# R7FA8D1BH register map
Vendor: Renesas; Series: RA8; File version: 1.2
CPU: CM85 r0p0, little endian, MPU, FPU, VTOR, 4 interrupt priority bits
Registers are 32-bit, read-write, reset 0x0 unless marked. A register's access mark holds for its fields unless they carry their own. Offsets are from the block's base; [hi:lo] are bit positions; {n}, {i} and the like mark numbered series; 'fields as' and 'values as' point back to an identical list.

## CANFD0 (part 2 of 2) — CANFD Module 0
Base 0x40380000
Same registers: CANFD1 0x40382000, CANFD0_NS 0x50380000, CANFD1_NS 0x50382000
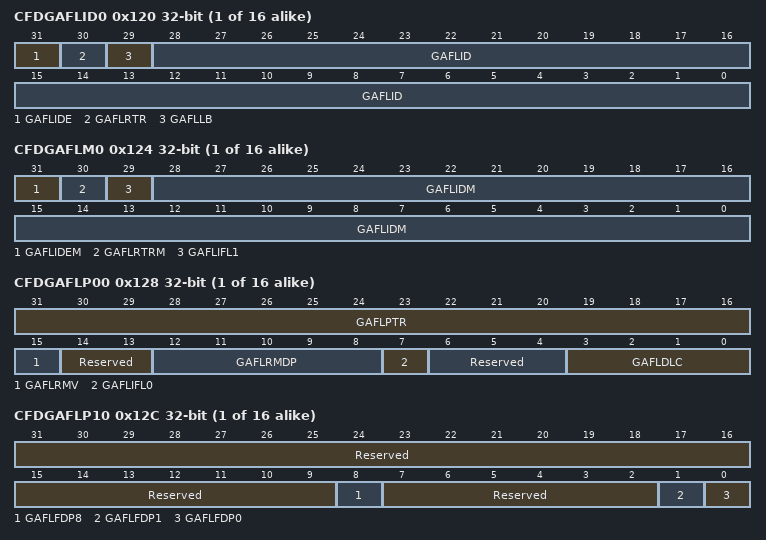
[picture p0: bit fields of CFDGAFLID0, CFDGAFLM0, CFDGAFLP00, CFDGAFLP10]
{0x120+0x10*i} CFDGAFLID{i} (i=0..15) — Global Acceptance Filter List ID Registers r = [1...10]h
  [31] GAFLIDE — Global Acceptance Filter List Entry IDE Field
    0=Standard Identifier of Rule entry ID is valid for acceptance filtering; 1=Extended Identifier of Rule entry ID is valid for acceptance filtering
  [30] GAFLRTR — Global Acceptance Filter List Entry RTR Field
    0=Data Frame; 1=Remote Frame
  [29] GAFLLB — Global Acceptance Filter List Entry Loopback Configuration
    0=Global Acceptance Filter List entry ID for acceptance filtering has attribute ‘RX’; 1=Global Acceptance Filter List entry ID for acceptance filtering has attribute ‘TX’
  [28:0] GAFLID — Global Acceptance Filter List Entry ID Field
{0x124+0x10*i} CFDGAFLM{i} (i=0..15) — Global Acceptance Filter List Mask Registers r = [1...10]h
  [31] GAFLIDEM — Global Acceptance Filter List IDE Mask
    0=IDE bit is not considered for ID matching; 1=IDE bit is considered for ID matching
  [30] GAFLRTRM — Global Acceptance Filter List Entry RTR Mask
    0=RTR bit is not considered for ID matching; 1=RTR bit is considered for ID matching
  [29] GAFLIFL1 — Global Acceptance Filter List Information Label 1
  [28:0] GAFLIDM — Global Acceptance Filter List ID Mask Field
{0x128+0x10*i} CFDGAFLP0{i} (i=0..15) — Global Acceptance Filter List Pointer 0 Registers r = [1...10]h
  [31:16] GAFLPTR — Global Acceptance Filter List Pointer Field
    values as CFDGAFLM0.GAFLRTRM
  [15] GAFLRMV — Global Acceptance Filter List RX Message Buffer Valid
    0=Global Acceptance Filter List Single Message Buffer Direction Pointer is invalid; 1=Global Acceptance Filter List Single Message Buffer Direction Pointer is valid
  [14:13] Reserved — These bits are read as 00. The write value should be 00.
  [12:8] GAFLRMDP — Global Acceptance Filter List RX Message Buffer Direction Pointer
  [7] GAFLIFL0 — Global Acceptance Filter List Information Label 0
  [6:4] Reserved — These bits are read as 000. The write value should be 000.
  [3:0] GAFLDLC — Global Acceptance Filter List DLC Field
{0x12C+0x10*i} CFDGAFLP1{i} (i=0..15) — Global Acceptance Filter List Pointer 1 Registers r = [1...10]h
  [31:9] Reserved — These bits are read as 00000000000000000000000. The write value should be 00000000000000000000000.
  [8] GAFLFDP8 — Global Acceptance Filter List FIFO Direction Pointer (GAFLFDP[8])
  [7:2] Reserved — These bits are read as 000000. The write value should be 000000.
  [1] GAFLFDP1 — Global Acceptance Filter List FIFO Direction Pointer (GAFLFDP[1])
  [0] GAFLFDP0 — Global Acceptance Filter List FIFO Direction Pointer (GAFLFDP[0])
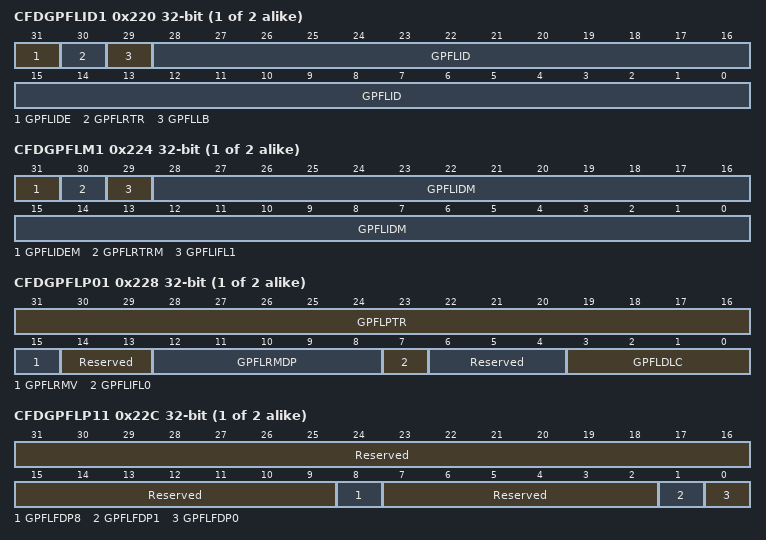
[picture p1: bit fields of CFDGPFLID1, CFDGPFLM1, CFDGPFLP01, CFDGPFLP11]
{0x1FC+0x24*i} CFDGPFLID{i} (i=1..2) — Global Pretended Network Filter List ID Registers s = [1…2]h
  [31] GPFLIDE — Global Pretended Network Filter List IDE Field
    values as CFDGAFLID0.GAFLIDE
  [30] GPFLRTR — Global Pretended Network Filter List Entry RTR Field
    0=Data Frame; 1=Remote Frame
  [29] GPFLLB — Global Pretended Network Filter List Entry Loopback Configuration
    0=Global Pretended Network Filter List entry ID for acceptance filtering has attribute ‘RX’; 1=Global Pretended Network Filter List entry ID for acceptance filtering has attribute ‘TX’
  [28:0] GPFLID — Global Pretended Network Filter List ID Field
{0x200+0x24*i} CFDGPFLM{i} (i=1..2) — Global Pretended Network Filter List MASK Registers s = [1…2]h
  [31] GPFLIDEM — Global Pretended Network Filter List IDE Mask
    values as CFDGAFLM0.GAFLIDEM
  [30] GPFLRTRM — Global Pretended Network Filter List Entry RTR Mask
    values as CFDGAFLM0.GAFLRTRM
  [29] GPFLIFL1 — Global Pretended Network Filter List Information Label 1
  [28:0] GPFLIDM — Global Pretended Network Filter List ID Mask Field
{0x204+0x24*i} CFDGPFLP0{i} (i=1..2) — Global Pretended Network Filter List Pointer 0 Registers s = [1…2]h
  [31:16] GPFLPTR — Global Pretended Network Filter List Pointer Field
  [15] GPFLRMV — Global Pretended Network Filter List RX Message Buffer Valid
    0=Global Pretended Network Filter List Single Message Buffer Direction Pointer is invalid; 1=Global Pretended Network Filter List Single Message Buffer Direction Pointer is valid
  [14:13] Reserved — These bits are read as 00. The write value should be 00.
  [12:8] GPFLRMDP — Global Pretended Network Filter List RX Message Buffer Direction Pointer
  [7] GPFLIFL0 — Global Pretended Network Filter List Information Label 0
  [6:4] Reserved — These bits are read as 000. The write value should be 000.
  [3:0] GPFLDLC — Global Pretended Network Filter List DLC Field
{0x208+0x24*i} CFDGPFLP1{i} (i=1..2) — Global Pretended Network Filter List Pointer 1 Registers s = [1…2]h
  [31:9] Reserved — These bits are read as 00000000000000000000000. The write value should be 00000000000000000000000.
  [8] GPFLFDP8 — Global Pretended Network Filter List FIFO Direction Pointer [8]
  [7:2] Reserved — These bits are read as 000000. The write value should be 000000.
  [1] GPFLFDP1 — Global Pretended Network Filter List FIFO Direction Pointer [1]
  [0] GPFLFDP0 — Global Pretended Network Filter List FIFO Direction Pointer [0]
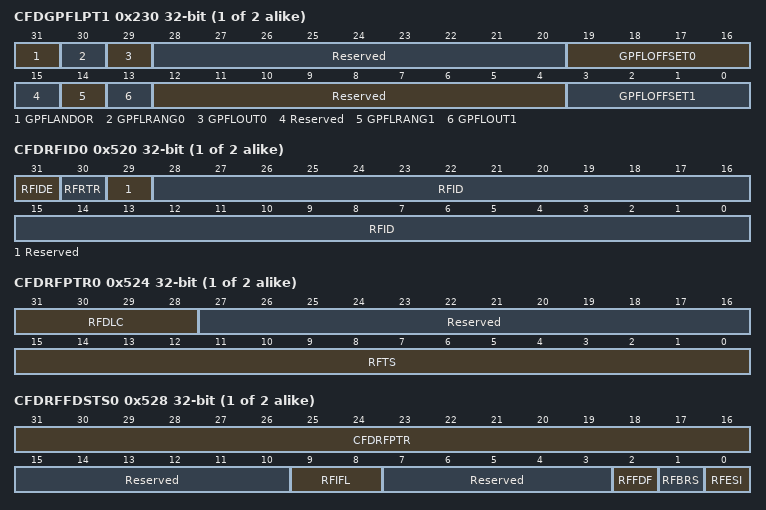
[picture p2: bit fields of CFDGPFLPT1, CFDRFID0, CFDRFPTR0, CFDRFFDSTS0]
{0x20C+0x24*i} CFDGPFLPT{i} (i=1..2) — Global Pretended Network Filter List Filter Type Registers s = [1…2]h
  [31] GPFLANDOR — Global Pretended Network filter conditions of the filters 0 and 1
    0=Both of filters 0 and 1 are successful; 1=One of the filter 0 or 1 is successful
  [30] GPFLRANG0 — Global Pretended Network filter comparison conditions of the filter0
    0=payload data match filter; 1=upper / lower filter
  [29] GPFLOUT0 — Global Pretended Network filter conditions of upper / lower filter of the filter0
    0=Within the range of upper limit and lower limit; 1=Outside of the range of upper limit and lower limit
  [28:20] Reserved — These bits are read as 000000000. The write value should be 000000000.
  [19:16] GPFLOFFSET0 — Global Pretended Network filter offset value of the filter0
  [15] Reserved — This bit is read as 0. The write value should be 0.
  [14] GPFLRANG1 — Global Pretended Network filter comparison conditions of the filter1
    0=payload data match filter; 1=upper / lower filter
  [13] GPFLOUT1 — Global Pretended Network filter conditions of upper / lower filter of the filter1
    values as GPFLOUT0
  [12:4] Reserved — These bits are read as 000000000. The write value should be 000000000.
  [3:0] GPFLOFFSET1 — Global Pretended Network filter offset value of the filter1
{0x210+0x24*i} CFDGPFLPD0{i} (i=1..2) — Global Pretended Network Filter List Payload Data 0 Registers s = [1…2]h
  [31:0] FDATA — Pretended Network Filter List Filter data
{0x214+0x24*i} CFDGPFLPM0{i} (i=1..2) — Global Pretended Network Filter List Payload Mask 0 Registers s = [1…2]h
  [31:0] FMASK — Pretended Network Filter List Filter data mask field
{0x218+0x24*i} CFDGPFLPD1{i} (i=1..2) — Global Pretended Network Filter List Payload Data 1 Registers s = [1…2]h
  [31:0] FDATA — Pretended Network Filter List Filter data
{0x21C+0x24*i} CFDGPFLPM1{i} (i=1..2) — Global Pretended Network Filter List Payload Mask 1 Registers s = [1…2]h
  [31:0] FMASK — Pretended Network Filter List Filter data mask field
{0x280+4i} CFDRPGACC{i} (i=0..63) — RAM Test Page Access Registers
  [31:0] RDTA — RAM Data Test Access
{0x520+0x4C*i} CFDRFID{i} (i=0..1) ro — RX FIFO Access ID Registers
  [31] RFIDE — RX FIFO Buffer IDE Bit
    0=STD-ID has been received; 1=EXT-ID has been received
  [30] RFRTR — RX FIFO Buffer RTR Bit
    0=Data Frame; 1=Remote Frame
  [29] Reserved — This bit is read as 0.
  [28:0] RFID — RX FIFO Buffer ID Field
{0x524+0x4C*i} CFDRFPTR{i} (i=0..1) ro — RX FIFO Access Pointer Register
  [31:28] RFDLC — RX FIFO Buffer DLC Field
    0=Data Frame; 1=Remote Frame
  [27:16] Reserved — These bits are read as 000000000000.
  [15:0] RFTS — RX FIFO Timestamp Value
{0x528+0x4C*i} CFDRFFDSTS{i} (i=0..1) ro — RX FIFO Access CAN-FD Status Register
  [31:16] CFDRFPTR — RX FIFO Buffer Pointer Field
  [15:10] Reserved — These bits are read as 000000.
  [9:8] RFIFL — RX FIFO Buffer Information label Field
  [7:3] Reserved — These bits are read as 00000.
  [2] RFFDF — CAN FD Format bit
    0=Non CAN-FD frame received; 1=CAN-FD frame received
  [1] RFBRS — Bit Rate Switch bit
    0=CAN-FD frame received with no bit rate switch; 1=CAN-FD frame received with bit rate switch
  [0] RFESI — Error State Indicator bit
    0=CAN-FD frame received from error active node; 1=CAN-FD frame received from error passive node
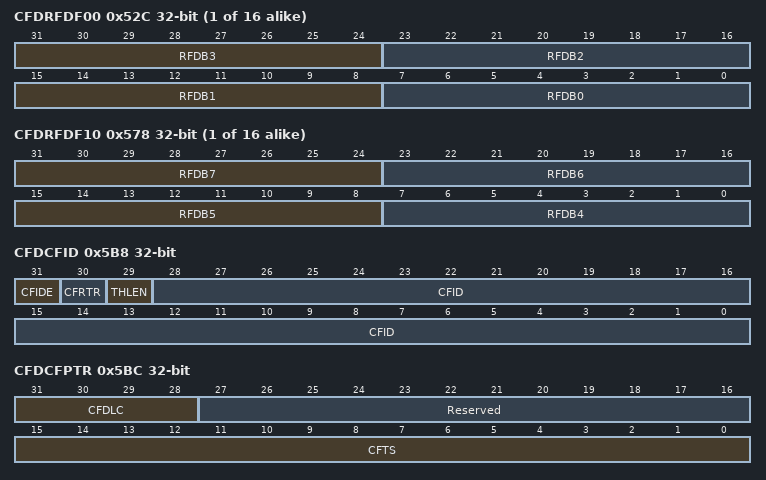
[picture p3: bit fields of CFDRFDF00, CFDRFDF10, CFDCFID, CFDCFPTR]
{0x52C+4i} CFDRFDF0{i} (i=0..15) ro — RX FIFO Access Data Field p Registers
  [31:24] RFDB3 — RX FIFO Buffer Data Byte ((p*q)+(q-1))
    0=Data Frame; 1=Remote Frame
  [23:16] RFDB2 — RX FIFO Buffer Data Byte ((p*q)+(q-2))
    0=Data Frame; 1=Remote Frame
  [15:8] RFDB1 — RX FIFO Buffer Data Byte ((p*q)+(q-3))
    0=Data Frame; 1=Remote Frame
  [7:0] RFDB0 — RX FIFO Buffer Data Byte ((p*q)+(q-4))
{0x578+4i} CFDRFDF1{i} (i=0..15) ro — RX FIFO Access Data Field p Registers
  [31:24] RFDB7 — RX FIFO Buffer Data Byte ((p*q)+(q-1))
    0=Data Frame; 1=Remote Frame
  [23:16] RFDB6 — RX FIFO Buffer Data Byte ((p*q)+(q-2))
    0=Data Frame; 1=Remote Frame
  [15:8] RFDB5 — RX FIFO Buffer Data Byte ((p*q)+(q-3))
    0=Data Frame; 1=Remote Frame
  [7:0] RFDB4 — RX FIFO Buffer Data Byte ((p*q)+(q-4))
0x5B8 CFDCFID — Common FIFO Access ID Registers
  [31] CFIDE — Common FIFO Buffer IDE Bit
    0=STD-ID will be transmitted or has been received; 1=EXT-ID will be transmitted or has been received
  [30] CFRTR — Common FIFO Buffer RTR Bit
    0=Data Frame; 1=Remote Frame
  [29] THLEN — THL Entry enable
    0=Entry will not be stored in THL after successful TX; 1=Entry will be stored in THL after successful TX
  [28:0] CFID — Common FIFO Buffer ID Field
0x5BC CFDCFPTR — Common FIFO Access Pointer Registers
  [31:28] CFDLC — Common FIFO Buffer DLC Field
    0=Data Frame; 1=Remote Frame
  [27:16] Reserved — These bits are read as 000000000000. The write value should be 000000000000.
  [15:0] CFTS — Common FIFO Timestamp Value
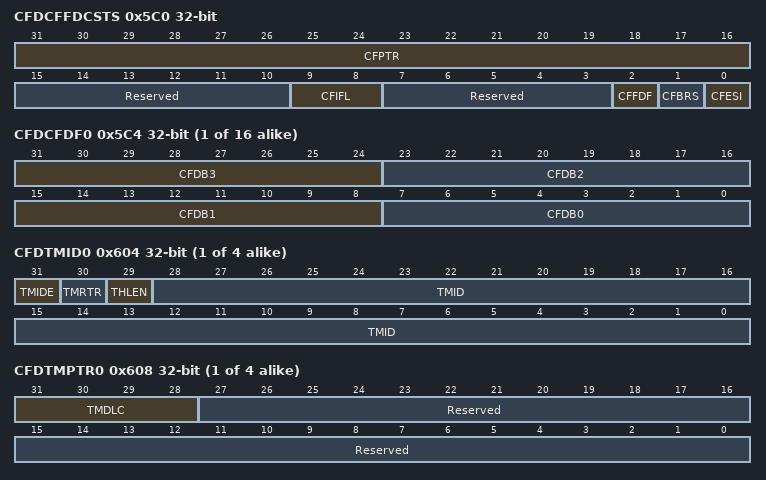
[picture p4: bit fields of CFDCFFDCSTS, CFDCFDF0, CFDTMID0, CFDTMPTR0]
0x5C0 CFDCFFDCSTS — Common FIFO Access CAN-FD Control/Status Register
  [31:16] CFPTR — Common FIFO Buffer Pointer Field
  [15:10] Reserved — These bits are read as 000000. The write value should be 000000.
  [9:8] CFIFL — COMMON FIFO Buffer Information label Field
  [7:3] Reserved — These bits are read as 00000. The write value should be 00000.
  [2] CFFDF — CAN FD Format bit
    0=Non CAN-FD frame received; 1=CAN-FD frame received
  [1] CFBRS — Bit Rate Switch bit
    values as CFDRFFDSTS0.RFBRS
  [0] CFESI — Error State Indicator bit
    values as CFDRFFDSTS0.RFESI
{0x5C4+4i} CFDCFDF{i} (i=0..15) — Common FIFO Access Data Field p Registers
  [31:24] CFDB{4i+3} — Common FIFO Buffer Data Byte ((p*q)+(q-1))
    0=Data Frame; 1=Remote Frame
  [23:16] CFDB{4i+2} — Common FIFO Buffer Data Byte ((p*q)+(q-2))
    0=Data Frame; 1=Remote Frame
  [15:8] CFDB{4i+1} — Common FIFO Buffer Data Byte ((p*q)+(q-3))
    0=Data Frame; 1=Remote Frame
  [7:0] CFDB{4i} — Common FIFO Buffer Data Byte ((p*q)+(q-4))
{0x604+0x4C*i} CFDTMID{i} (i=0..3) — TX Message Buffer ID Registers
  [31] TMIDE — TX Message Buffer IDE Bit
    0=STD-ID will be transmitted; 1=EXT-ID will be transmitted
  [30] TMRTR — TX Message Buffer RTR Bit
    0=Data Frame; 1=Remote Frame
  [29] THLEN — Tx History List Entry
    values as CFDCFID.THLEN
  [28:0] TMID — TX Message Buffer ID Field
{0x608+0x4C*i} CFDTMPTR{i} (i=0..3) — TX Message Buffer Pointer Registers
  [31:28] TMDLC — TX Message Buffer DLC Field
    0=Data Frame; 1=Remote Frame
  [27:0] Reserved — These bits are read as 0000000000000000000000000000. The write value should be 0000000000000000000000000000.
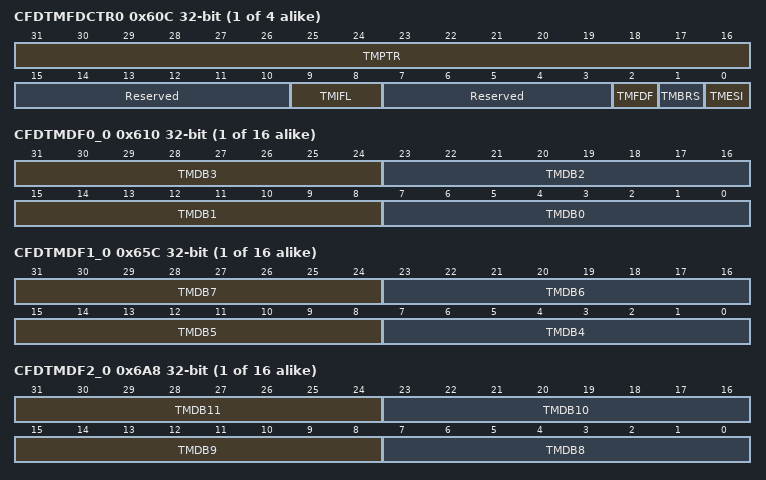
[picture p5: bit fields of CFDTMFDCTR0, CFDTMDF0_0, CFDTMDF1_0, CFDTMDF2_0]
{0x60C+0x4C*i} CFDTMFDCTR{i} (i=0..3) — TX Message Buffer CAN-FD Control Register
  [31:16] TMPTR — TX Message Buffer Pointer Field
  [15:10] Reserved — These bits are read as 000000. The write value should be 000000.
  [9:8] TMIFL — TX Message Buffer Information Label Field
  [7:3] Reserved — These bits are read as 00000. The write value should be 00000.
  [2] TMFDF — CAN FD Format bit
    0=Non CAN-FD frame received; 1=CAN-FD frame received
  [1] TMBRS — Bit Rate Switch bit
    values as CFDRFFDSTS0.RFBRS
  [0] TMESI — Error State Indicator bit
    values as CFDRFFDSTS0.RFESI
{0x610+4i} CFDTMDF0_{i} (i=0..15) — TX Message Buffer Data Field p Registers
  [31:24] TMDB3 — TX Message Buffer Data Byte ((p*q)+(q-1))
  [23:16] TMDB2 — TX Message Buffer Data Byte ((p*q)+(q-2))
  [15:8] TMDB1 — TX Message Buffer Data Byte ((p*q)+(q-3))
  [7:0] TMDB0 — TX Message Buffer Data Byte ((p*q)+(q-4))
{0x65C+4i} CFDTMDF1_{i} (i=0..15) — TX Message Buffer Data Field p Registers
  [31:24] TMDB7 — TX Message Buffer Data Byte ((p*q)+(q-1))
  [23:16] TMDB6 — TX Message Buffer Data Byte ((p*q)+(q-2))
  [15:8] TMDB5 — TX Message Buffer Data Byte ((p*q)+(q-3))
  [7:0] TMDB4 — TX Message Buffer Data Byte ((p*q)+(q-4))
{0x6A8+4i} CFDTMDF2_{i} (i=0..15) — TX Message Buffer Data Field p Registers
  [31:24] TMDB11 — TX Message Buffer Data Byte ((p*q)+(q-1))
  [23:16] TMDB10 — TX Message Buffer Data Byte ((p*q)+(q-2))
  [15:8] TMDB9 — TX Message Buffer Data Byte ((p*q)+(q-3))
  [7:0] TMDB8 — TX Message Buffer Data Byte ((p*q)+(q-4))
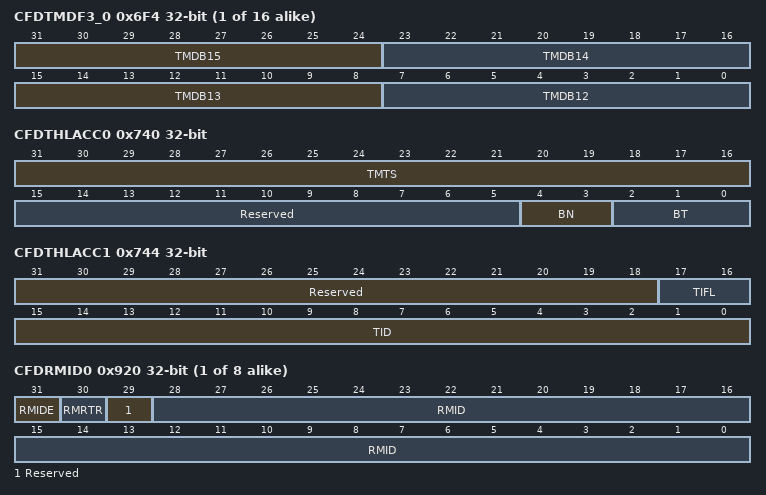
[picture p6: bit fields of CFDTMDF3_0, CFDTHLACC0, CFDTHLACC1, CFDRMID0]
{0x6F4+4i} CFDTMDF3_{i} (i=0..15) — TX Message Buffer Data Field p Registers
  [31:24] TMDB15 — TX Message Buffer Data Byte ((p*q)+(q-1))
  [23:16] TMDB14 — TX Message Buffer Data Byte ((p*q)+(q-2))
  [15:8] TMDB13 — TX Message Buffer Data Byte ((p*q)+(q-3))
  [7:0] TMDB12 — TX Message Buffer Data Byte ((p*q)+(q-4))
0x740 CFDTHLACC0 ro — Channel 0 TX History List Access Registers0
  [31:16] TMTS — Transmit Timestamp
  [15:5] Reserved — These bits are read as 00000000000.
  [4:3] BN — Buffer No.
  [2:0] BT — Buffer Type
    1=Flat TX Message Buffer; 2=TX FIFO MB No and GW FIFO MB No; 4=TX Queue MB No. (Only RX version)
0x744 CFDTHLACC1 ro — Channel 0 TX History List Access Registers1
  [31:18] Reserved — These bits are read as 00000000000000.
  [17:16] TIFL — Transmit Information Label
  [15:0] TID — Transmit ID
{0x920+0x4C*i} CFDRMID{i} (i=0..7) ro — RX Message Buffer ID Registers
  [31] RMIDE — RX Message Buffer IDE Bit
    0=STD-ID is stored; 1=EXT-ID is stored
  [30] RMRTR — RX Message Buffer RTR Bit
    0=Data Frame; 1=Remote Frame
  [29] Reserved — This bit is read as 0.
  [28:0] RMID — RX Message Buffer ID Field
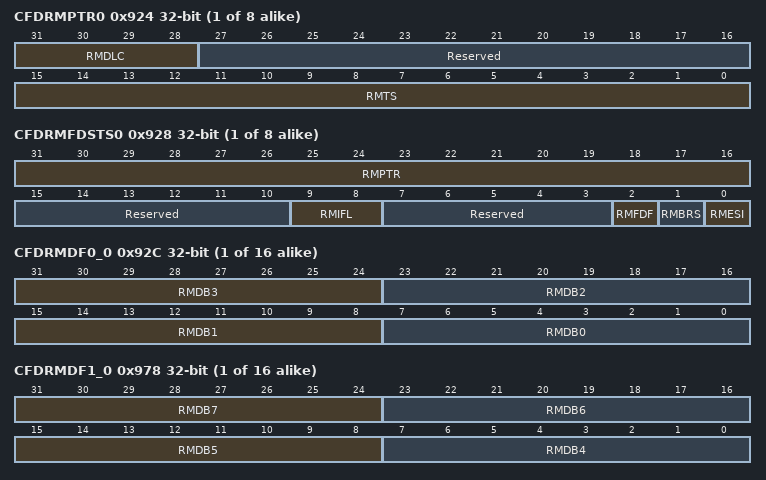
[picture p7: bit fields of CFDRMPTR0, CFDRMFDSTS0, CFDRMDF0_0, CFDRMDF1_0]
{0x924+0x4C*i} CFDRMPTR{i} (i=0..7) ro — RX Message Buffer Pointer Registers
  [31:28] RMDLC — RX Message Buffer DLC Field
    0=Data Frame; 1=Remote Frame
  [27:16] Reserved — These bits are read as 000000000000.
  [15:0] RMTS — RX Message Buffer Timestamp Field
{0x928+0x4C*i} CFDRMFDSTS{i} (i=0..7) ro — RX Message Buffer CAN-FD Status Register
  [31:16] RMPTR — RX Message Buffer Pointer Field
  [15:10] Reserved — These bits are read as 000000.
  [9:8] RMIFL — RX Message Buffer Information label Field
  [7:3] Reserved — These bits are read as 00000.
  [2] RMFDF — CAN FD Format bit
    0=Non CAN-FD frame received; 1=CAN-FD frame received
  [1] RMBRS — Bit Rate Switch bit
    values as CFDRFFDSTS0.RFBRS
  [0] RMESI — Error State Indicator bit
    values as CFDRFFDSTS0.RFESI
{0x92C+4i} CFDRMDF0_{i} (i=0..15) ro — RX Message Buffer Data Field p Registers
  [31:24] RMDB3 — RX Message Buffer Data Byte ((p*q)+(q-1))
    0=Data Frame; 1=Remote Frame
  [23:16] RMDB2 — RX Message Buffer Data Byte ((p*q)+(q-2))
    0=Data Frame; 1=Remote Frame
  [15:8] RMDB1 — RX Message Buffer Data Byte ((p*q)+(q-3))
    0=Data Frame; 1=Remote Frame
  [7:0] RMDB0 — RX Message Buffer Data Byte ((p*q)+(q-4))
{0x978+4i} CFDRMDF1_{i} (i=0..15) ro — RX Message Buffer Data Field p Registers
  [31:24] RMDB7 — RX Message Buffer Data Byte ((p*q)+(q-1))
    0=Data Frame; 1=Remote Frame
  [23:16] RMDB6 — RX Message Buffer Data Byte ((p*q)+(q-2))
    0=Data Frame; 1=Remote Frame
  [15:8] RMDB5 — RX Message Buffer Data Byte ((p*q)+(q-3))
    0=Data Frame; 1=Remote Frame
  [7:0] RMDB4 — RX Message Buffer Data Byte ((p*q)+(q-4))
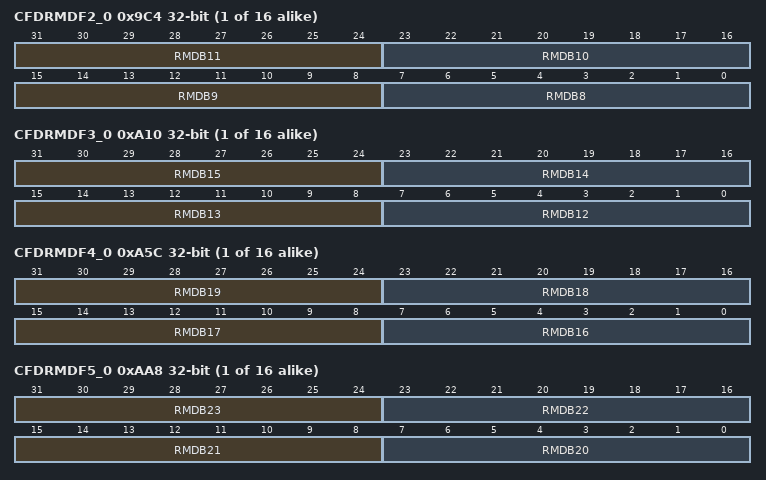
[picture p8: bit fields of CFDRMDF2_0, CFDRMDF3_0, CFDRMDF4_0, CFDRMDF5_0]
{0x9C4+4i} CFDRMDF2_{i} (i=0..15) ro — RX Message Buffer Data Field p Registers
  [31:24] RMDB11 — RX Message Buffer Data Byte ((p*q)+(q-1))
    0=Data Frame; 1=Remote Frame
  [23:16] RMDB10 — RX Message Buffer Data Byte ((p*q)+(q-2))
    0=Data Frame; 1=Remote Frame
  [15:8] RMDB9 — RX Message Buffer Data Byte ((p*q)+(q-3))
    0=Data Frame; 1=Remote Frame
  [7:0] RMDB8 — RX Message Buffer Data Byte ((p*q)+(q-4))
{0xA10+4i} CFDRMDF3_{i} (i=0..15) ro — RX Message Buffer Data Field p Registers
  [31:24] RMDB15 — RX Message Buffer Data Byte ((p*q)+(q-1))
    0=Data Frame; 1=Remote Frame
  [23:16] RMDB14 — RX Message Buffer Data Byte ((p*q)+(q-2))
    0=Data Frame; 1=Remote Frame
  [15:8] RMDB13 — RX Message Buffer Data Byte ((p*q)+(q-3))
    0=Data Frame; 1=Remote Frame
  [7:0] RMDB12 — RX Message Buffer Data Byte ((p*q)+(q-4))
{0xA5C+4i} CFDRMDF4_{i} (i=0..15) ro — RX Message Buffer Data Field p Registers
  [31:24] RMDB19 — RX Message Buffer Data Byte ((p*q)+(q-1))
    0=Data Frame; 1=Remote Frame
  [23:16] RMDB18 — RX Message Buffer Data Byte ((p*q)+(q-2))
    0=Data Frame; 1=Remote Frame
  [15:8] RMDB17 — RX Message Buffer Data Byte ((p*q)+(q-3))
    0=Data Frame; 1=Remote Frame
  [7:0] RMDB16 — RX Message Buffer Data Byte ((p*q)+(q-4))
{0xAA8+4i} CFDRMDF5_{i} (i=0..15) ro — RX Message Buffer Data Field p Registers
  [31:24] RMDB23 — RX Message Buffer Data Byte ((p*q)+(q-1))
    0=Data Frame; 1=Remote Frame
  [23:16] RMDB22 — RX Message Buffer Data Byte ((p*q)+(q-2))
    0=Data Frame; 1=Remote Frame
  [15:8] RMDB21 — RX Message Buffer Data Byte ((p*q)+(q-3))
    0=Data Frame; 1=Remote Frame
  [7:0] RMDB20 — RX Message Buffer Data Byte ((p*q)+(q-4))
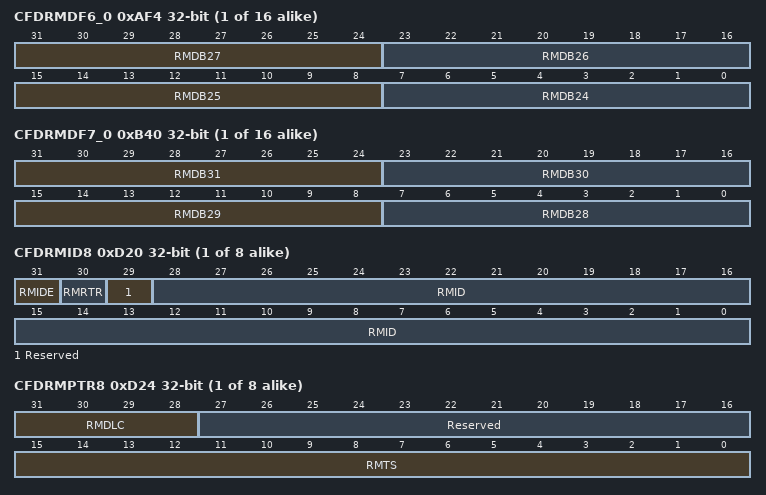
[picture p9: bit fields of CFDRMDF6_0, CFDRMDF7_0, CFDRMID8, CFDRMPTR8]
{0xAF4+4i} CFDRMDF6_{i} (i=0..15) ro — RX Message Buffer Data Field p Registers
  [31:24] RMDB27 — RX Message Buffer Data Byte ((p*q)+(q-1))
    0=Data Frame; 1=Remote Frame
  [23:16] RMDB26 — RX Message Buffer Data Byte ((p*q)+(q-2))
    0=Data Frame; 1=Remote Frame
  [15:8] RMDB25 — RX Message Buffer Data Byte ((p*q)+(q-3))
    0=Data Frame; 1=Remote Frame
  [7:0] RMDB24 — RX Message Buffer Data Byte ((p*q)+(q-4))
{0xB40+4i} CFDRMDF7_{i} (i=0..15) ro — RX Message Buffer Data Field p Registers
  [31:24] RMDB31 — RX Message Buffer Data Byte ((p*q)+(q-1))
    0=Data Frame; 1=Remote Frame
  [23:16] RMDB30 — RX Message Buffer Data Byte ((p*q)+(q-2))
    0=Data Frame; 1=Remote Frame
  [15:8] RMDB29 — RX Message Buffer Data Byte ((p*q)+(q-3))
    0=Data Frame; 1=Remote Frame
  [7:0] RMDB28 — RX Message Buffer Data Byte ((p*q)+(q-4))
{0xAC0+0x4C*i} CFDRMID{i} (i=8..15) ro — RX Message Buffer ID Registers
  fields as CFDRMID0
{0xAC4+0x4C*i} CFDRMPTR{i} (i=8..15) ro — RX Message Buffer Pointer Registers
  fields as CFDRMPTR0
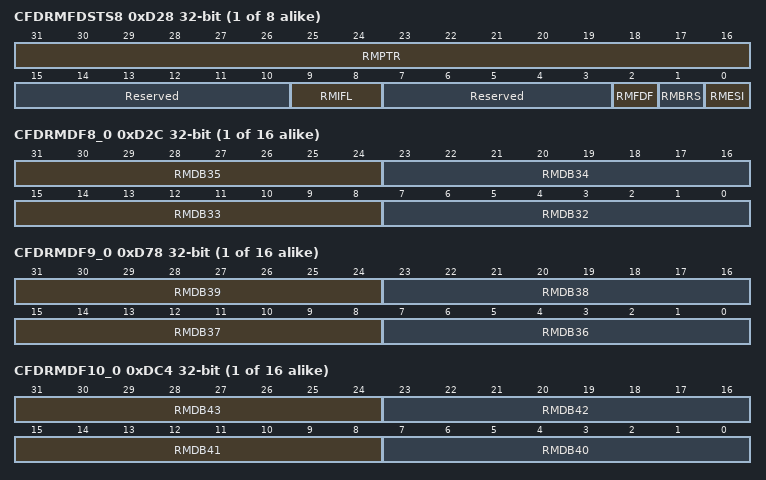
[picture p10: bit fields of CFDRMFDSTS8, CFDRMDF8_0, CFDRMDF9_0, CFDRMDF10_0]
{0xAC8+0x4C*i} CFDRMFDSTS{i} (i=8..15) ro — RX Message Buffer CAN-FD Status Register
  fields as CFDRMFDSTS0
{0xD2C+4i} CFDRMDF8_{i} (i=0..15) ro — RX Message Buffer Data Field p Registers
  [31:24] RMDB35 — RX Message Buffer Data Byte ((p*q)+(q-1))
    0=Data Frame; 1=Remote Frame
  [23:16] RMDB34 — RX Message Buffer Data Byte ((p*q)+(q-2))
    0=Data Frame; 1=Remote Frame
  [15:8] RMDB33 — RX Message Buffer Data Byte ((p*q)+(q-3))
    0=Data Frame; 1=Remote Frame
  [7:0] RMDB32 — RX Message Buffer Data Byte ((p*q)+(q-4))
{0xD78+4i} CFDRMDF9_{i} (i=0..15) ro — RX Message Buffer Data Field p Registers
  [31:24] RMDB39 — RX Message Buffer Data Byte ((p*q)+(q-1))
    0=Data Frame; 1=Remote Frame
  [23:16] RMDB38 — RX Message Buffer Data Byte ((p*q)+(q-2))
    0=Data Frame; 1=Remote Frame
  [15:8] RMDB37 — RX Message Buffer Data Byte ((p*q)+(q-3))
    0=Data Frame; 1=Remote Frame
  [7:0] RMDB36 — RX Message Buffer Data Byte ((p*q)+(q-4))
{0xDC4+4i} CFDRMDF10_{i} (i=0..15) ro — RX Message Buffer Data Field p Registers
  [31:24] RMDB43 — RX Message Buffer Data Byte ((p*q)+(q-1))
    0=Data Frame; 1=Remote Frame
  [23:16] RMDB42 — RX Message Buffer Data Byte ((p*q)+(q-2))
    0=Data Frame; 1=Remote Frame
  [15:8] RMDB41 — RX Message Buffer Data Byte ((p*q)+(q-3))
    0=Data Frame; 1=Remote Frame
  [7:0] RMDB40 — RX Message Buffer Data Byte ((p*q)+(q-4))
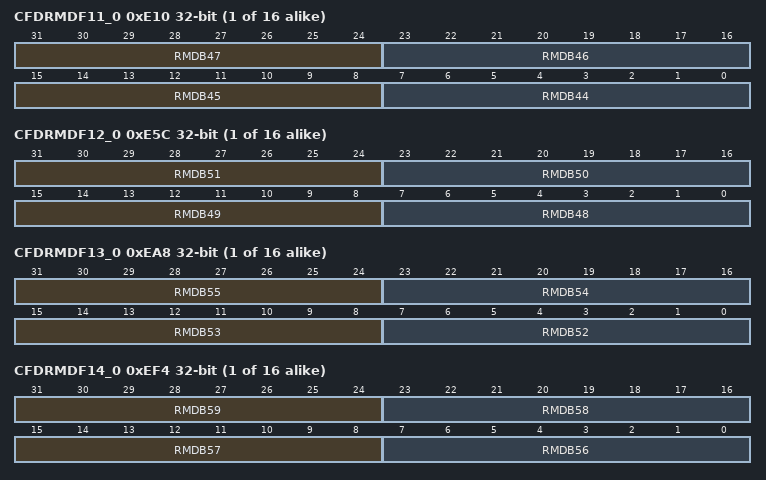
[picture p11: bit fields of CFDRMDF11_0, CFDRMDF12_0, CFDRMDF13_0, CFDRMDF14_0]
{0xE10+4i} CFDRMDF11_{i} (i=0..15) ro — RX Message Buffer Data Field p Registers
  [31:24] RMDB47 — RX Message Buffer Data Byte ((p*q)+(q-1))
    0=Data Frame; 1=Remote Frame
  [23:16] RMDB46 — RX Message Buffer Data Byte ((p*q)+(q-2))
    0=Data Frame; 1=Remote Frame
  [15:8] RMDB45 — RX Message Buffer Data Byte ((p*q)+(q-3))
    0=Data Frame; 1=Remote Frame
  [7:0] RMDB44 — RX Message Buffer Data Byte ((p*q)+(q-4))
{0xE5C+4i} CFDRMDF12_{i} (i=0..15) ro — RX Message Buffer Data Field p Registers
  [31:24] RMDB51 — RX Message Buffer Data Byte ((p*q)+(q-1))
    0=Data Frame; 1=Remote Frame
  [23:16] RMDB50 — RX Message Buffer Data Byte ((p*q)+(q-2))
    0=Data Frame; 1=Remote Frame
  [15:8] RMDB49 — RX Message Buffer Data Byte ((p*q)+(q-3))
    0=Data Frame; 1=Remote Frame
  [7:0] RMDB48 — RX Message Buffer Data Byte ((p*q)+(q-4))
{0xEA8+4i} CFDRMDF13_{i} (i=0..15) ro — RX Message Buffer Data Field p Registers
  [31:24] RMDB55 — RX Message Buffer Data Byte ((p*q)+(q-1))
    0=Data Frame; 1=Remote Frame
  [23:16] RMDB54 — RX Message Buffer Data Byte ((p*q)+(q-2))
    0=Data Frame; 1=Remote Frame
  [15:8] RMDB53 — RX Message Buffer Data Byte ((p*q)+(q-3))
    0=Data Frame; 1=Remote Frame
  [7:0] RMDB52 — RX Message Buffer Data Byte ((p*q)+(q-4))
{0xEF4+4i} CFDRMDF14_{i} (i=0..15) ro — RX Message Buffer Data Field p Registers
  [31:24] RMDB59 — RX Message Buffer Data Byte ((p*q)+(q-1))
    0=Data Frame; 1=Remote Frame
  [23:16] RMDB58 — RX Message Buffer Data Byte ((p*q)+(q-2))
    0=Data Frame; 1=Remote Frame
  [15:8] RMDB57 — RX Message Buffer Data Byte ((p*q)+(q-3))
    0=Data Frame; 1=Remote Frame
  [7:0] RMDB56 — RX Message Buffer Data Byte ((p*q)+(q-4))
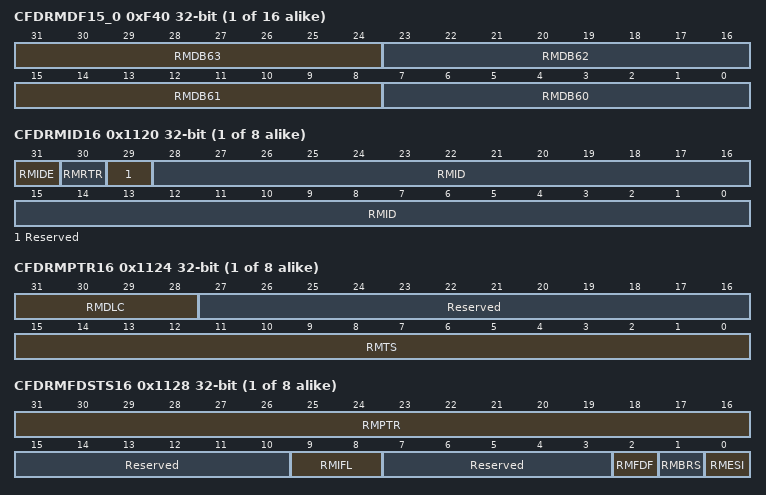
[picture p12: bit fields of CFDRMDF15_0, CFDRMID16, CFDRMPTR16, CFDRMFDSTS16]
{0xF40+4i} CFDRMDF15_{i} (i=0..15) ro — RX Message Buffer Data Field p Registers
  [31:24] RMDB63 — RX Message Buffer Data Byte ((p*q)+(q-1))
    0=Data Frame; 1=Remote Frame
  [23:16] RMDB62 — RX Message Buffer Data Byte ((p*q)+(q-2))
    0=Data Frame; 1=Remote Frame
  [15:8] RMDB61 — RX Message Buffer Data Byte ((p*q)+(q-3))
    0=Data Frame; 1=Remote Frame
  [7:0] RMDB60 — RX Message Buffer Data Byte ((p*q)+(q-4))
{0xC60+0x4C*i} CFDRMID{i} (i=16..23) ro — RX Message Buffer ID Registers
  fields as CFDRMID0
{0xC64+0x4C*i} CFDRMPTR{i} (i=16..23) ro — RX Message Buffer Pointer Registers
  fields as CFDRMPTR0
{0xC68+0x4C*i} CFDRMFDSTS{i} (i=16..23) ro — RX Message Buffer CAN-FD Status Register
  fields as CFDRMFDSTS0
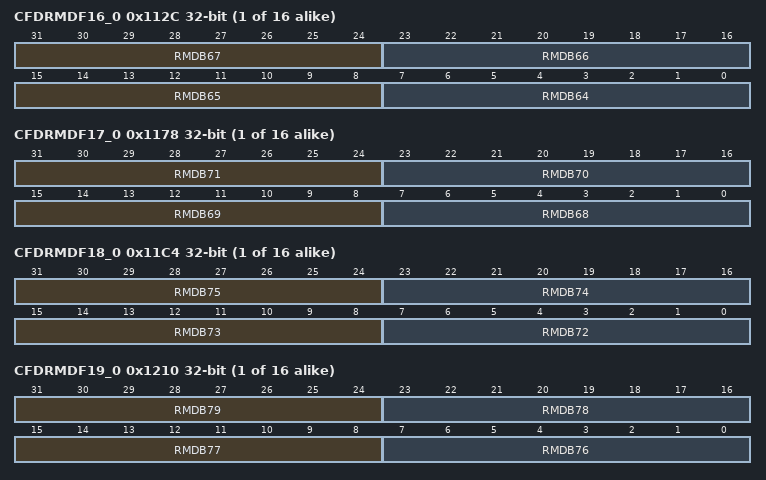
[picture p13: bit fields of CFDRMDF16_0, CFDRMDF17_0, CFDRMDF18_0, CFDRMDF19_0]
{0x112C+4i} CFDRMDF16_{i} (i=0..15) ro — RX Message Buffer Data Field p Registers
  [31:24] RMDB67 — RX Message Buffer Data Byte ((p*q)+(q-1))
    0=Data Frame; 1=Remote Frame
  [23:16] RMDB66 — RX Message Buffer Data Byte ((p*q)+(q-2))
    0=Data Frame; 1=Remote Frame
  [15:8] RMDB65 — RX Message Buffer Data Byte ((p*q)+(q-3))
    0=Data Frame; 1=Remote Frame
  [7:0] RMDB64 — RX Message Buffer Data Byte ((p*q)+(q-4))
{0x1178+4i} CFDRMDF17_{i} (i=0..15) ro — RX Message Buffer Data Field p Registers
  [31:24] RMDB71 — RX Message Buffer Data Byte ((p*q)+(q-1))
    0=Data Frame; 1=Remote Frame
  [23:16] RMDB70 — RX Message Buffer Data Byte ((p*q)+(q-2))
    0=Data Frame; 1=Remote Frame
  [15:8] RMDB69 — RX Message Buffer Data Byte ((p*q)+(q-3))
    0=Data Frame; 1=Remote Frame
  [7:0] RMDB68 — RX Message Buffer Data Byte ((p*q)+(q-4))
{0x11C4+4i} CFDRMDF18_{i} (i=0..15) ro — RX Message Buffer Data Field p Registers
  [31:24] RMDB75 — RX Message Buffer Data Byte ((p*q)+(q-1))
    0=Data Frame; 1=Remote Frame
  [23:16] RMDB74 — RX Message Buffer Data Byte ((p*q)+(q-2))
    0=Data Frame; 1=Remote Frame
  [15:8] RMDB73 — RX Message Buffer Data Byte ((p*q)+(q-3))
    0=Data Frame; 1=Remote Frame
  [7:0] RMDB72 — RX Message Buffer Data Byte ((p*q)+(q-4))
{0x1210+4i} CFDRMDF19_{i} (i=0..15) ro — RX Message Buffer Data Field p Registers
  [31:24] RMDB79 — RX Message Buffer Data Byte ((p*q)+(q-1))
    0=Data Frame; 1=Remote Frame
  [23:16] RMDB78 — RX Message Buffer Data Byte ((p*q)+(q-2))
    0=Data Frame; 1=Remote Frame
  [15:8] RMDB77 — RX Message Buffer Data Byte ((p*q)+(q-3))
    0=Data Frame; 1=Remote Frame
  [7:0] RMDB76 — RX Message Buffer Data Byte ((p*q)+(q-4))
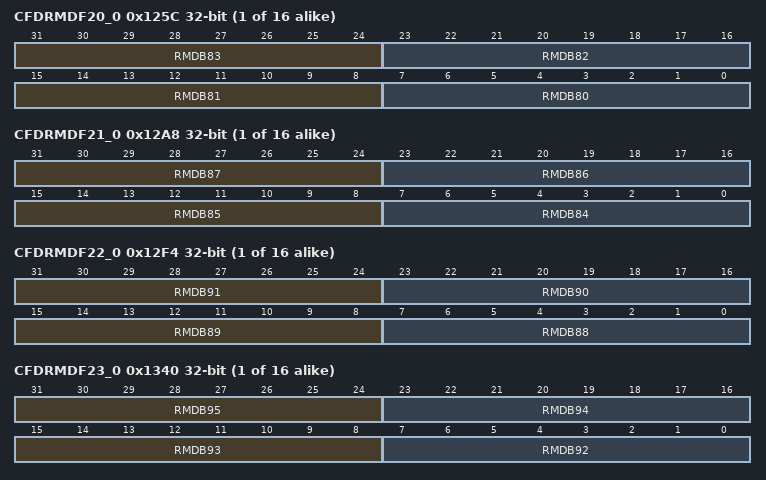
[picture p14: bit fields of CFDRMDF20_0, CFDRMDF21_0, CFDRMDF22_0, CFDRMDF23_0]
{0x125C+4i} CFDRMDF20_{i} (i=0..15) ro — RX Message Buffer Data Field p Registers
  [31:24] RMDB83 — RX Message Buffer Data Byte ((p*q)+(q-1))
    0=Data Frame; 1=Remote Frame
  [23:16] RMDB82 — RX Message Buffer Data Byte ((p*q)+(q-2))
    0=Data Frame; 1=Remote Frame
  [15:8] RMDB81 — RX Message Buffer Data Byte ((p*q)+(q-3))
    0=Data Frame; 1=Remote Frame
  [7:0] RMDB80 — RX Message Buffer Data Byte ((p*q)+(q-4))
{0x12A8+4i} CFDRMDF21_{i} (i=0..15) ro — RX Message Buffer Data Field p Registers
  [31:24] RMDB87 — RX Message Buffer Data Byte ((p*q)+(q-1))
    0=Data Frame; 1=Remote Frame
  [23:16] RMDB86 — RX Message Buffer Data Byte ((p*q)+(q-2))
    0=Data Frame; 1=Remote Frame
  [15:8] RMDB85 — RX Message Buffer Data Byte ((p*q)+(q-3))
    0=Data Frame; 1=Remote Frame
  [7:0] RMDB84 — RX Message Buffer Data Byte ((p*q)+(q-4))
{0x12F4+4i} CFDRMDF22_{i} (i=0..15) ro — RX Message Buffer Data Field p Registers
  [31:24] RMDB91 — RX Message Buffer Data Byte ((p*q)+(q-1))
    0=Data Frame; 1=Remote Frame
  [23:16] RMDB90 — RX Message Buffer Data Byte ((p*q)+(q-2))
    0=Data Frame; 1=Remote Frame
  [15:8] RMDB89 — RX Message Buffer Data Byte ((p*q)+(q-3))
    0=Data Frame; 1=Remote Frame
  [7:0] RMDB88 — RX Message Buffer Data Byte ((p*q)+(q-4))
{0x1340+4i} CFDRMDF23_{i} (i=0..15) ro — RX Message Buffer Data Field p Registers
  [31:24] RMDB95 — RX Message Buffer Data Byte ((p*q)+(q-1))
    0=Data Frame; 1=Remote Frame
  [23:16] RMDB94 — RX Message Buffer Data Byte ((p*q)+(q-2))
    0=Data Frame; 1=Remote Frame
  [15:8] RMDB93 — RX Message Buffer Data Byte ((p*q)+(q-3))
    0=Data Frame; 1=Remote Frame
  [7:0] RMDB92 — RX Message Buffer Data Byte ((p*q)+(q-4))
{0xE00+0x4C*i} CFDRMID{i} (i=24..31) ro — RX Message Buffer ID Registers
  fields as CFDRMID0
{0xE04+0x4C*i} CFDRMPTR{i} (i=24..31) ro — RX Message Buffer Pointer Registers
  fields as CFDRMPTR0
{0xE08+0x4C*i} CFDRMFDSTS{i} (i=24..31) ro — RX Message Buffer CAN-FD Status Register
  fields as CFDRMFDSTS0
{0x152C+4i} CFDRMDF24_{i} (i=0..15) ro — RX Message Buffer Data Field p Registers
  [31:24] RMDB99 — RX Message Buffer Data Byte ((p*q)+(q-1))
    0=Data Frame; 1=Remote Frame
  [23:16] RMDB98 — RX Message Buffer Data Byte ((p*q)+(q-2))
    0=Data Frame; 1=Remote Frame
  [15:8] RMDB97 — RX Message Buffer Data Byte ((p*q)+(q-3))
    0=Data Frame; 1=Remote Frame
  [7:0] RMDB96 — RX Message Buffer Data Byte ((p*q)+(q-4))
{0x1578+4i} CFDRMDF25_{i} (i=0..15) ro — RX Message Buffer Data Field p Registers
  [31:24] RMDB103 — RX Message Buffer Data Byte ((p*q)+(q-1))
    0=Data Frame; 1=Remote Frame
  [23:16] RMDB102 — RX Message Buffer Data Byte ((p*q)+(q-2))
    0=Data Frame; 1=Remote Frame
  [15:8] RMDB101 — RX Message Buffer Data Byte ((p*q)+(q-3))
    0=Data Frame; 1=Remote Frame
  [7:0] RMDB100 — RX Message Buffer Data Byte ((p*q)+(q-4))
{0x15C4+4i} CFDRMDF26_{i} (i=0..15) ro — RX Message Buffer Data Field p Registers
  [31:24] RMDB107 — RX Message Buffer Data Byte ((p*q)+(q-1))
    0=Data Frame; 1=Remote Frame
  [23:16] RMDB106 — RX Message Buffer Data Byte ((p*q)+(q-2))
    0=Data Frame; 1=Remote Frame
  [15:8] RMDB105 — RX Message Buffer Data Byte ((p*q)+(q-3))
    0=Data Frame; 1=Remote Frame
  [7:0] RMDB104 — RX Message Buffer Data Byte ((p*q)+(q-4))
{0x1610+4i} CFDRMDF27_{i} (i=0..15) ro — RX Message Buffer Data Field p Registers
  [31:24] RMDB111 — RX Message Buffer Data Byte ((p*q)+(q-1))
    0=Data Frame; 1=Remote Frame
  [23:16] RMDB110 — RX Message Buffer Data Byte ((p*q)+(q-2))
    0=Data Frame; 1=Remote Frame
  [15:8] RMDB109 — RX Message Buffer Data Byte ((p*q)+(q-3))
    0=Data Frame; 1=Remote Frame
  [7:0] RMDB108 — RX Message Buffer Data Byte ((p*q)+(q-4))
{0x165C+4i} CFDRMDF28_{i} (i=0..15) ro — RX Message Buffer Data Field p Registers
  [31:24] RMDB115 — RX Message Buffer Data Byte ((p*q)+(q-1))
    0=Data Frame; 1=Remote Frame
  [23:16] RMDB114 — RX Message Buffer Data Byte ((p*q)+(q-2))
    0=Data Frame; 1=Remote Frame
  [15:8] RMDB113 — RX Message Buffer Data Byte ((p*q)+(q-3))
    0=Data Frame; 1=Remote Frame
  [7:0] RMDB112 — RX Message Buffer Data Byte ((p*q)+(q-4))
{0x16A8+4i} CFDRMDF29_{i} (i=0..15) ro — RX Message Buffer Data Field p Registers
  [31:24] RMDB119 — RX Message Buffer Data Byte ((p*q)+(q-1))
    0=Data Frame; 1=Remote Frame
  [23:16] RMDB118 — RX Message Buffer Data Byte ((p*q)+(q-2))
    0=Data Frame; 1=Remote Frame
  [15:8] RMDB117 — RX Message Buffer Data Byte ((p*q)+(q-3))
    0=Data Frame; 1=Remote Frame
  [7:0] RMDB116 — RX Message Buffer Data Byte ((p*q)+(q-4))
{0x16F4+4i} CFDRMDF30_{i} (i=0..15) ro — RX Message Buffer Data Field p Registers
  [31:24] RMDB123 — RX Message Buffer Data Byte ((p*q)+(q-1))
    0=Data Frame; 1=Remote Frame
  [23:16] RMDB122 — RX Message Buffer Data Byte ((p*q)+(q-2))
    0=Data Frame; 1=Remote Frame
  [15:8] RMDB121 — RX Message Buffer Data Byte ((p*q)+(q-3))
    0=Data Frame; 1=Remote Frame
  [7:0] RMDB120 — RX Message Buffer Data Byte ((p*q)+(q-4))
{0x1740+4i} CFDRMDF31_{i} (i=0..15) ro — RX Message Buffer Data Field p Registers
  [31:24] RMDB127 — RX Message Buffer Data Byte ((p*q)+(q-1))
    0=Data Frame; 1=Remote Frame
  [23:16] RMDB126 — RX Message Buffer Data Byte ((p*q)+(q-2))
    0=Data Frame; 1=Remote Frame
  [15:8] RMDB125 — RX Message Buffer Data Byte ((p*q)+(q-3))
    0=Data Frame; 1=Remote Frame
  [7:0] RMDB124 — RX Message Buffer Data Byte ((p*q)+(q-4))
{0x1920+0x4C*i} CFDRFIDE{i} (i=0..1) ro — RX FIFO Access ID Registers for Emulation
  fields as CFDRFID0
{0x1924+0x4C*i} CFDRFPTRE{i} (i=0..1) ro — RX FIFO Access Pointer Registers for Emulation
  fields as CFDRFPTR0
{0x1928+0x4C*i} CFDRFFDSTSE{i} (i=0..1) ro — RX FIFO Access CAN-FD Status Registers for Emulation
  fields as CFDRFFDSTS0
{0x192C+0x4C*i} CFDRFDF0E{i} (i=0..1) ro — RX FIFO Access Data Field p Registers for Emulation
  fields as CFDRFDF00
{0x1930+0x4C*i} CFDRFDF1E{i} (i=0..1) ro — RX FIFO Access Data Field p Registers for Emulation
  fields as CFDRFDF10
{0x1934+0x4C*i} CFDRFDF2E{i} (i=0..1) ro — RX FIFO Access Data Field p Registers for Emulation
  [31:24] RFDB11 — RX FIFO Buffer Data Byte ((p*q)+(q-1))
    0=Data Frame; 1=Remote Frame
  [23:16] RFDB10 — RX FIFO Buffer Data Byte ((p*q)+(q-2))
    0=Data Frame; 1=Remote Frame
  [15:8] RFDB9 — RX FIFO Buffer Data Byte ((p*q)+(q-3))
    0=Data Frame; 1=Remote Frame
  [7:0] RFDB8 — RX FIFO Buffer Data Byte ((p*q)+(q-4))
{0x1938+0x4C*i} CFDRFDF3E{i} (i=0..1) ro — RX FIFO Access Data Field p Registers for Emulation
  [31:24] RFDB15 — RX FIFO Buffer Data Byte ((p*q)+(q-1))
    0=Data Frame; 1=Remote Frame
  [23:16] RFDB14 — RX FIFO Buffer Data Byte ((p*q)+(q-2))
    0=Data Frame; 1=Remote Frame
  [15:8] RFDB13 — RX FIFO Buffer Data Byte ((p*q)+(q-3))
    0=Data Frame; 1=Remote Frame
  [7:0] RFDB12 — RX FIFO Buffer Data Byte ((p*q)+(q-4))
{0x193C+0x4C*i} CFDRFDF4E{i} (i=0..1) ro — RX FIFO Access Data Field p Registers for Emulation
  [31:24] RFDB19 — RX FIFO Buffer Data Byte ((p*q)+(q-1))
    0=Data Frame; 1=Remote Frame
  [23:16] RFDB18 — RX FIFO Buffer Data Byte ((p*q)+(q-2))
    0=Data Frame; 1=Remote Frame
  [15:8] RFDB17 — RX FIFO Buffer Data Byte ((p*q)+(q-3))
    0=Data Frame; 1=Remote Frame
  [7:0] RFDB16 — RX FIFO Buffer Data Byte ((p*q)+(q-4))
{0x1940+0x4C*i} CFDRFDF5E{i} (i=0..1) ro — RX FIFO Access Data Field p Registers for Emulation
  [31:24] RFDB23 — RX FIFO Buffer Data Byte ((p*q)+(q-1))
    0=Data Frame; 1=Remote Frame
  [23:16] RFDB22 — RX FIFO Buffer Data Byte ((p*q)+(q-2))
    0=Data Frame; 1=Remote Frame
  [15:8] RFDB21 — RX FIFO Buffer Data Byte ((p*q)+(q-3))
    0=Data Frame; 1=Remote Frame
  [7:0] RFDB20 — RX FIFO Buffer Data Byte ((p*q)+(q-4))
{0x1944+0x4C*i} CFDRFDF6E{i} (i=0..1) ro — RX FIFO Access Data Field p Registers for Emulation
  [31:24] RFDB27 — RX FIFO Buffer Data Byte ((p*q)+(q-1))
    0=Data Frame; 1=Remote Frame
  [23:16] RFDB26 — RX FIFO Buffer Data Byte ((p*q)+(q-2))
    0=Data Frame; 1=Remote Frame
  [15:8] RFDB25 — RX FIFO Buffer Data Byte ((p*q)+(q-3))
    0=Data Frame; 1=Remote Frame
  [7:0] RFDB24 — RX FIFO Buffer Data Byte ((p*q)+(q-4))
{0x1948+0x4C*i} CFDRFDF7E{i} (i=0..1) ro — RX FIFO Access Data Field p Registers for Emulation
  [31:24] RFDB31 — RX FIFO Buffer Data Byte ((p*q)+(q-1))
    0=Data Frame; 1=Remote Frame
  [23:16] RFDB30 — RX FIFO Buffer Data Byte ((p*q)+(q-2))
    0=Data Frame; 1=Remote Frame
  [15:8] RFDB29 — RX FIFO Buffer Data Byte ((p*q)+(q-3))
    0=Data Frame; 1=Remote Frame
  [7:0] RFDB28 — RX FIFO Buffer Data Byte ((p*q)+(q-4))
{0x194C+0x4C*i} CFDRFDF8E{i} (i=0..1) ro — RX FIFO Access Data Field p Registers for Emulation
  [31:24] RFDB35 — RX FIFO Buffer Data Byte ((p*q)+(q-1))
    0=Data Frame; 1=Remote Frame
  [23:16] RFDB34 — RX FIFO Buffer Data Byte ((p*q)+(q-2))
    0=Data Frame; 1=Remote Frame
  [15:8] RFDB33 — RX FIFO Buffer Data Byte ((p*q)+(q-3))
    0=Data Frame; 1=Remote Frame
  [7:0] RFDB32 — RX FIFO Buffer Data Byte ((p*q)+(q-4))
{0x1950+0x4C*i} CFDRFDF9E{i} (i=0..1) ro — RX FIFO Access Data Field p Registers for Emulation
  [31:24] RFDB39 — RX FIFO Buffer Data Byte ((p*q)+(q-1))
    0=Data Frame; 1=Remote Frame
  [23:16] RFDB38 — RX FIFO Buffer Data Byte ((p*q)+(q-2))
    0=Data Frame; 1=Remote Frame
  [15:8] RFDB37 — RX FIFO Buffer Data Byte ((p*q)+(q-3))
    0=Data Frame; 1=Remote Frame
  [7:0] RFDB36 — RX FIFO Buffer Data Byte ((p*q)+(q-4))
{0x1954+0x4C*i} CFDRFDF10E{i} (i=0..1) ro — RX FIFO Access Data Field p Registers for Emulation
  [31:24] RFDB43 — RX FIFO Buffer Data Byte ((p*q)+(q-1))
    0=Data Frame; 1=Remote Frame
  [23:16] RFDB42 — RX FIFO Buffer Data Byte ((p*q)+(q-2))
    0=Data Frame; 1=Remote Frame
  [15:8] RFDB41 — RX FIFO Buffer Data Byte ((p*q)+(q-3))
    0=Data Frame; 1=Remote Frame
  [7:0] RFDB40 — RX FIFO Buffer Data Byte ((p*q)+(q-4))
{0x1958+0x4C*i} CFDRFDF11E{i} (i=0..1) ro — RX FIFO Access Data Field p Registers for Emulation
  [31:24] RFDB47 — RX FIFO Buffer Data Byte ((p*q)+(q-1))
    0=Data Frame; 1=Remote Frame
  [23:16] RFDB46 — RX FIFO Buffer Data Byte ((p*q)+(q-2))
    0=Data Frame; 1=Remote Frame
  [15:8] RFDB45 — RX FIFO Buffer Data Byte ((p*q)+(q-3))
    0=Data Frame; 1=Remote Frame
  [7:0] RFDB44 — RX FIFO Buffer Data Byte ((p*q)+(q-4))
{0x195C+0x4C*i} CFDRFDF12E{i} (i=0..1) ro — RX FIFO Access Data Field p Registers for Emulation
  [31:24] RFDB51 — RX FIFO Buffer Data Byte ((p*q)+(q-1))
    0=Data Frame; 1=Remote Frame
  [23:16] RFDB50 — RX FIFO Buffer Data Byte ((p*q)+(q-2))
    0=Data Frame; 1=Remote Frame
  [15:8] RFDB49 — RX FIFO Buffer Data Byte ((p*q)+(q-3))
    0=Data Frame; 1=Remote Frame
  [7:0] RFDB48 — RX FIFO Buffer Data Byte ((p*q)+(q-4))
{0x1960+0x4C*i} CFDRFDF13E{i} (i=0..1) ro — RX FIFO Access Data Field p Registers for Emulation
  [31:24] RFDB55 — RX FIFO Buffer Data Byte ((p*q)+(q-1))
    0=Data Frame; 1=Remote Frame
  [23:16] RFDB54 — RX FIFO Buffer Data Byte ((p*q)+(q-2))
    0=Data Frame; 1=Remote Frame
  [15:8] RFDB53 — RX FIFO Buffer Data Byte ((p*q)+(q-3))
    0=Data Frame; 1=Remote Frame
  [7:0] RFDB52 — RX FIFO Buffer Data Byte ((p*q)+(q-4))
{0x1964+0x4C*i} CFDRFDF14E{i} (i=0..1) ro — RX FIFO Access Data Field p Registers for Emulation
  [31:24] RFDB59 — RX FIFO Buffer Data Byte ((p*q)+(q-1))
    0=Data Frame; 1=Remote Frame
  [23:16] RFDB58 — RX FIFO Buffer Data Byte ((p*q)+(q-2))
    0=Data Frame; 1=Remote Frame
  [15:8] RFDB57 — RX FIFO Buffer Data Byte ((p*q)+(q-3))
    0=Data Frame; 1=Remote Frame
  [7:0] RFDB56 — RX FIFO Buffer Data Byte ((p*q)+(q-4))
{0x1968+0x4C*i} CFDRFDF15E{i} (i=0..1) ro — RX FIFO Access Data Field p Registers for Emulation
  [31:24] RFDB63 — RX FIFO Buffer Data Byte ((p*q)+(q-1))
    0=Data Frame; 1=Remote Frame
  [23:16] RFDB62 — RX FIFO Buffer Data Byte ((p*q)+(q-2))
    0=Data Frame; 1=Remote Frame
  [15:8] RFDB61 — RX FIFO Buffer Data Byte ((p*q)+(q-3))
    0=Data Frame; 1=Remote Frame
  [7:0] RFDB60 — RX FIFO Buffer Data Byte ((p*q)+(q-4))
0x19B8 CFDCFIDE — Common FIFO Access ID Register for Emulation
  fields as CFDCFID
0x19BC CFDCFPTRE — Common FIFO Access Pointer Register for Emulation
  fields as CFDCFPTR
0x19C0 CFDCFFDCSTSE — Common FIFO Access CAN-FD Control/Status Register for Emulation
  fields as CFDCFFDCSTS
{0x19C4+4i} CFDCFDF{i}E (i=0..15) — Common FIFO Access Data Field p Registers
  [31:24] CFDB3 — Common FIFO Buffer Data Byte ((p*q)+(q-1))
    0=Data Frame; 1=Remote Frame
  [23:16] CFDB2 — Common FIFO Buffer Data Byte ((p*q)+(q-2))
    0=Data Frame; 1=Remote Frame
  [15:8] CFDB1 — Common FIFO Buffer Data Byte ((p*q)+(q-3))
    0=Data Frame; 1=Remote Frame
  [7:0] CFDB0 — Common FIFO Buffer Data Byte ((p*q)+(q-4))
